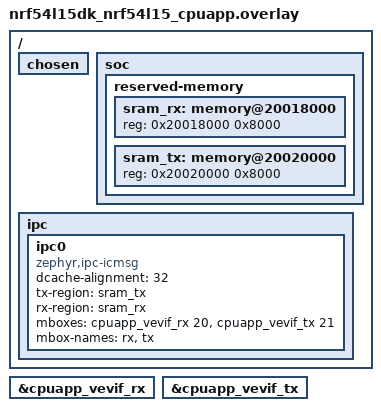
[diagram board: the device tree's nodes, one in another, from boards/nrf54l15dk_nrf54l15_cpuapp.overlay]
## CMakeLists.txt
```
#
# Copyright (c) 2022 Nordic Semiconductor
#
# SPDX-License-Identifier: LicenseRef-Nordic-5-Clause
#

cmake_minimum_required(VERSION 3.20.0)

find_package(Zephyr REQUIRED HINTS $ENV{ZEPHYR_BASE})
project(event_manager_proxy)

add_subdirectory(common_events)
add_subdirectory(modules)

target_sources(app PRIVATE src/main.c)
```

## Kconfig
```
#
# Copyright (c) 2022 Nordic Semiconductor ASA
#
# SPDX-License-Identifier: LicenseRef-Nordic-5-Clause
#

menu "Zephyr Kernel"
source "Kconfig.zephyr"
endmenu

menu "Event manager proxy sample application settings"

config APP_EVENT_MANAGER_REMOTE_WAIT_TO
	int "Waiting period for the remote core to finish the initialization"
	range 10 5000
	default 1000
	help
	  The time to wait for second core to report its readiness to transport the events.
	  The time is given in milliseconds.

rsource "common_events/Kconfig"
rsource "modules/Kconfig"
endmenu
```

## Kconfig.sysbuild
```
#
# Copyright (c) 2023 Nordic Semiconductor ASA
#
# SPDX-License-Identifier: LicenseRef-Nordic-5-Clause
#

source "share/sysbuild/Kconfig"

config REMOTE_BOARD
	string "The board used for remote target"
	default "nrf5340dk/nrf5340/cpunet" if BOARD_NRF5340DK_NRF5340_CPUAPP
	default "nrf5340dk/nrf5340/cpunet" if BOARD_NRF5340DK_NRF5340_CPUAPP_NS
	default "nrf54h20dk/nrf54h20/cpuppr" if BOARD_NRF54H20DK_NRF54H20_CPUAPP
	default "nrf54l15dk/nrf54l15/cpuflpr" if BOARD_NRF54L15DK_NRF54L15_CPUAPP
	default "nrf54lm20pdk/nrf54lm20a/cpuflpr" if BOARD_NRF54LM20PDK_NRF54LM20A_CPUAPP
	default "nrf54lv10dk/nrf54lv10a/cpuflpr" if BOARD_NRF54LV10DK_NRF54LV10A_CPUAPP
	default "UNKNOWN"
```

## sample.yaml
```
sample:
  description: Sample showing usage of sending the events to another core via Event
    Manager Proxy
  name: Event Manager proxy sample

common:
  sysbuild: true
  tags:
    - ipc
    - ci_build
    - ci_samples_event_manager_proxy
  harness: console
  harness_config:
    type: multi_line
    ordered: false
    regex:
      - "Event Manager Proxy demo started"
      - "main: Event manager proxy started"
      - "main: All remotes ready"
      - "app_event_manager: e:config_event"
      - "main: Initialization finished successfully"
      - "app_event_manager: e:measurement_event"
      - "app_event_manager: e: control_event"
      - "stats: Control event count:"
      - "stats: Average value3:"

tests:
  sample.event_manager_proxy:
    platform_allow:
      - nrf5340dk/nrf5340/cpuapp
    integration_platforms:
      - nrf5340dk/nrf5340/cpuapp
  sample.event_manager_proxy.nrf5340dk_nrf5340_cpuapp.icmsg:
    platform_allow:
      - nrf5340dk/nrf5340/cpuapp
    integration_platforms:
      - nrf5340dk/nrf5340/cpuapp
    extra_args: FILE_SUFFIX=icmsg
  sample.event_manager_proxy.nrf54h20dk_cpuapp:
    platform_allow:
      - nrf54h20dk/nrf54h20/cpuapp
    integration_platforms:
      - nrf54h20dk/nrf54h20/cpuapp
    timeout: 20
  sample.event_manager_proxy.nrf54l_cpuapp_cpuflpr:
    extra_args:
      - event_manager_proxy_SNIPPET=nordic-flpr
    platform_allow:
      - nrf54l15dk/nrf54l15/cpuapp
      - nrf54lm20pdk/nrf54lm20a/cpuapp
      - nrf54lm20pdk@0.0.0/nrf54lm20a/cpuapp
      - nrf54lm20pdk@0.2.0/nrf54lm20a/cpuapp
      - nrf54lm20pdk@0.2.0.csp/nrf54lm20a/cpuapp
      - nrf54lv10dk/nrf54lv10a/cpuapp
      - nrf54lv10dk@0.0.0/nrf54lv10a/cpuapp
      - nrf54lv10dk@0.2.0/nrf54lv10a/cpuapp
    integration_platforms:
      - nrf54l15dk/nrf54l15/cpuapp
      - nrf54lm20pdk/nrf54lm20a/cpuapp
      - nrf54lv10dk/nrf54lv10a/cpuapp
```

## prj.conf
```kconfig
#
# Copyright (c) 2022 Nordic Semiconductor ASA
#
# SPDX-License-Identifier: LicenseRef-Nordic-5-Clause
#
# Enabling assert
CONFIG_ASSERT=y

# Logger configuration
CONFIG_LOG=y
CONFIG_LOG_BACKEND_UART=y

# Configuration required by Event Manager
CONFIG_APP_EVENT_MANAGER=y
CONFIG_EVENT_MANAGER_PROXY=y
CONFIG_HEAP_MEM_POOL_SIZE=4096
CONFIG_REBOOT=y

CONFIG_PRINTK=y

CONFIG_IPC_SERVICE=y
CONFIG_MBOX=y

# Simplify debugging
CONFIG_RESET_ON_FATAL_ERROR=n

###################################
# Application configuration
###################################

CONFIG_APP_CONFIG_EVENT=y
CONFIG_APP_MODULE_STATS_ENABLE=y
```

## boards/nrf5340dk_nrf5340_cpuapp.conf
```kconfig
#
# Copyright (c) 2022 Nordic Semiconductor ASA
#
# SPDX-License-Identifier: LicenseRef-Nordic-5-Clause
#

CONFIG_SOC_NRF53_CPUNET_ENABLE=y
CONFIG_OPENAMP_SLAVE=n
```

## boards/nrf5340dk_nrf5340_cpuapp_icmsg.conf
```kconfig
#
# Copyright (c) 2022 Nordic Semiconductor ASA
#
# SPDX-License-Identifier: LicenseRef-Nordic-5-Clause
#

CONFIG_SOC_NRF53_CPUNET_ENABLE=y
```

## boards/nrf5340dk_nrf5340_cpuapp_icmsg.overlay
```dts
/*
 * Copyright (c) 2022 Nordic Semiconductor ASA
 *
 * SPDX-License-Identifier: LicenseRef-Nordic-5-Clause
 */

/delete-node/ &ipc0;

/ {
	chosen {
		/delete-property/ zephyr,ipc_shm;
		/delete-property/ zephyr,bt-hci;
	};

	reserved-memory {
		/delete-node/ memory@20070000;

		sram_tx: memory@20070000 {
			reg = <0x20070000 0x0800>;
		};

		sram_rx: memory@20078000 {
			reg = <0x20078000 0x0800>;
		};
	};

	ipc0: ipc0 {
		compatible = "zephyr,ipc-icmsg";
		tx-region = <&sram_tx>;
		rx-region = <&sram_rx>;
		mboxes = <&mbox 0>, <&mbox 1>;
		mbox-names = "tx", "rx";
		status = "okay";
	};
};
```

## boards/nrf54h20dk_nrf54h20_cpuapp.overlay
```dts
/*
 * Copyright (c) 2024 Nordic Semiconductor ASA
 *
 * SPDX-License-Identifier: LicenseRef-Nordic-5-Clause
 */

/* Replace default ipc0 instance */
/delete-node/ &ipc0;

/* Enabled nodes required by IPC
 * Mbox for PPR target, one for each side and one IPC instance
 */

&cpuppr_vevif {
       status = "okay";
};

ipc0: &cpuapp_cpuppr_ipc {
	status = "okay";
};

/ {
	chosen {
		/delete-property/ zephyr,bt-hci;
	};
};

/* UART and RAM3 instance used by PPR should be enabled at build time
 * using nordic-ppr snippet.
 */
```

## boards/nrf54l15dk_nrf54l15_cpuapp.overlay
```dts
/*
 * Copyright (c) 2025 Nordic Semiconductor ASA
 *
 * SPDX-License-Identifier: LicenseRef-Nordic-5-Clause
 */

/ {
	chosen {
		/delete-property/ zephyr,bt-hci;
	};

	soc {
		reserved-memory {
			#address-cells = <1>;
			#size-cells = <1>;

			sram_rx: memory@20018000 {
				reg = <0x20018000 0x8000>;
			};

			sram_tx: memory@20020000 {
				reg = <0x20020000 0x8000>;
			};
		};
	};

	ipc {
		ipc0: ipc0 {
			compatible = "zephyr,ipc-icmsg";
			dcache-alignment = <32>;
			tx-region = <&sram_tx>;
			rx-region = <&sram_rx>;
			mboxes = <&cpuapp_vevif_rx 20>, <&cpuapp_vevif_tx 21>;
			mbox-names = "rx", "tx";
			status = "okay";
		};
	};
};

&cpuapp_vevif_rx {
	status = "okay";
};

&cpuapp_vevif_tx {
	status = "okay";
};
```

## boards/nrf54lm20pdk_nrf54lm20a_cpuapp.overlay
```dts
/*
 * Copyright (c) 2025 Nordic Semiconductor ASA
 *
 * SPDX-License-Identifier: LicenseRef-Nordic-5-Clause
 */

/ {
	chosen {
		/delete-property/ zephyr,bt-hci;
	};

	soc {
		reserved-memory {
			#address-cells = <1>;
			#size-cells = <1>;

			sram_rx: memory@20057c00 {
				reg = <0x20057c00 0x8000>;
			};

			sram_tx: memory@2005fc00 {
				reg = <0x2005fc00 0x8000>;
			};
		};
	};

	ipc {
		ipc0: ipc0 {
			compatible = "zephyr,ipc-icmsg";
			dcache-alignment = <32>;
			tx-region = <&sram_tx>;
			rx-region = <&sram_rx>;
			mboxes = <&cpuapp_vevif_rx 20>, <&cpuapp_vevif_tx 21>;
			mbox-names = "rx", "tx";
			status = "okay";
		};
	};
};

&cpuapp_vevif_rx {
	status = "okay";
};

&cpuapp_vevif_tx {
	status = "okay";
};
```

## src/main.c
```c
/*
 * Copyright (c) 2022 Nordic Semiconductor ASA
 *
 * SPDX-License-Identifier: LicenseRef-Nordic-5-Clause
 */

#include <zephyr/kernel.h>
#include <zephyr/device.h>

#include <zephyr/ipc/ipc_service.h>

#include <app_event_manager.h>
#include <event_manager_proxy.h>
#include <config_event.h>
#include <control_event.h>
#include <measurement_event.h>
#include <zephyr/logging/log.h>

#define MODULE main

LOG_MODULE_REGISTER(MODULE);

#define INIT_VALUE1 3

int main(void)
{
	int ret;
	const struct device *ipc_instance  = DEVICE_DT_GET(DT_NODELABEL(ipc0));

	printk("Event Manager Proxy demo started\n");
	LOG_INF("Starting");

	ret = app_event_manager_init();
	if (ret) {
		LOG_ERR("Event Manager not initialized, err: %d", ret);
		__ASSERT_NO_MSG(false);
		return 0;
	}
	LOG_INF("Event manager initialized");

	ret = event_manager_proxy_add_remote(ipc_instance);
	if (ret && ret != -EALREADY) {
		LOG_ERR("Cannot add remote: %d", ret);
		__ASSERT_NO_MSG(false);
		return 0;
	}
	LOG_INF("Event proxy remote added");

	/* Listen to the events from the remote */
	ret = EVENT_MANAGER_PROXY_SUBSCRIBE(ipc_instance, control_event);
	if (ret) {
		LOG_ERR("Cannot register to remote control_event: %d", ret);
		__ASSERT_NO_MSG(false);
		return 0;
	}
	LOG_INF("Event proxy control_event registered");
	ret = EVENT_MANAGER_PROXY_SUBSCRIBE(ipc_instance, measurement_event);
	if (ret) {
		LOG_ERR("Cannot register to remote measurement_event: %d", ret);
		__ASSERT_NO_MSG(false);
		return 0;
	}
	LOG_INF("Event proxy measurement_event registered");

	ret = event_manager_proxy_start();
	if (ret) {
		LOG_ERR("Cannot start event manager proxy: %d", ret);
		__ASSERT_NO_MSG(false);
		return 0;
	}
	LOG_INF("Event manager proxy started");

	/* Wait for all the remote cores to finish event proxy initialization */
	ret = event_manager_proxy_wait_for_remotes(K_MSEC(CONFIG_APP_EVENT_MANAGER_REMOTE_WAIT_TO));
	if (ret) {
		LOG_ERR("Error when waiting for remote: %d", ret);
		__ASSERT_NO_MSG(false);
		return 0;
	}
	LOG_INF("All remotes ready");

	/* Sending config event that should be received and processed by the remote */
	struct config_event *event = new_config_event();

	event->init_value1 = INIT_VALUE1;
	APP_EVENT_SUBMIT(event);

	LOG_INF("Initialization finished successfully");

	/* Main is not needed anymore - rest would be processed in events in stats module */
	return 0;
}
```
